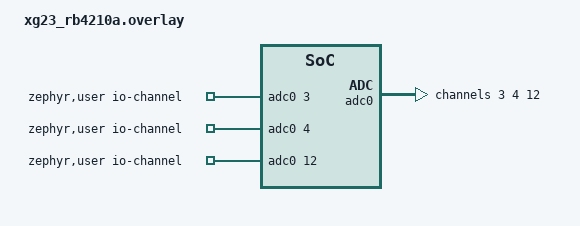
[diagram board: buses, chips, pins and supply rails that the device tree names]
/*
 * SPDX-License-Identifier: Apache-2.0
 *
 * Copyright (c) 2025 Silicon Laboratories Inc.
 */

#include <dt-bindings/adc/silabs-adc.h>

/ {
	zephyr,user {
		io-channels = <&adc0 3>, <&adc0 4>, <&adc0 12>;
	};
};

&pinctrl {
	adc0_default: adc0_default {
		group0 {
			/* Allocate odd Analog bus 0 on GPIO port B to IADC
			 * for access to pin PB3.
			 * Allocate odd Analog bus 1 on GPIO port A to IADC
			 * for access to pin PA7.
			 * Allocate even Analog bus 0 on GPIO port C/D to IADC
			 * for access to pin PD2.
			 */
			silabs,analog-bus = <ABUS_BODD0_IADC0>,
					    <ABUS_AODD1_IADC0>,
					    <ABUS_CDEVEN0_IADC0>;
		};
	};
};

&adc0 {
	pinctrl-0 = <&adc0_default>;
	pinctrl-names = "default";
	#address-cells = <1>;
	#size-cells = <0>;
	status = "okay";

	channel@3 {
		reg = <3>;
		zephyr,gain = "ADC_GAIN_1";
		zephyr,reference = "ADC_REF_INTERNAL";
		zephyr,acquisition-time = <ADC_ACQ_TIME_DEFAULT>;
		zephyr,resolution = <12>;
		zephyr,input-positive = <IADC_INPUT_AVDD>;
	};

	channel@4 {
		reg = <4>;
		zephyr,gain = "ADC_GAIN_1";
		zephyr,reference = "ADC_REF_VDD_1";
		zephyr,vref-mv = <3300>;
		zephyr,acquisition-time = <ADC_ACQ_TIME_DEFAULT>;
		zephyr,resolution = <12>;
		zephyr,input-positive = <IADC_INPUT_PB3>;
	};

	channel@c {
		reg = <12>;
		zephyr,gain = "ADC_GAIN_1";
		zephyr,reference = "ADC_REF_VDD_1";
		zephyr,vref-mv = <3300>;
		zephyr,acquisition-time = <ADC_ACQ_TIME_DEFAULT>;
		zephyr,resolution = <12>;
		zephyr,input-positive = <IADC_INPUT_PA7>; /* WPK EXP HEADER 13 */
		zephyr,input-negative = <IADC_INPUT_PD2>; /* WPK EXP HEADER 9 */
	};
};
